VERSION ""

NS_ :

BS_:

BU_: Vector__XXX

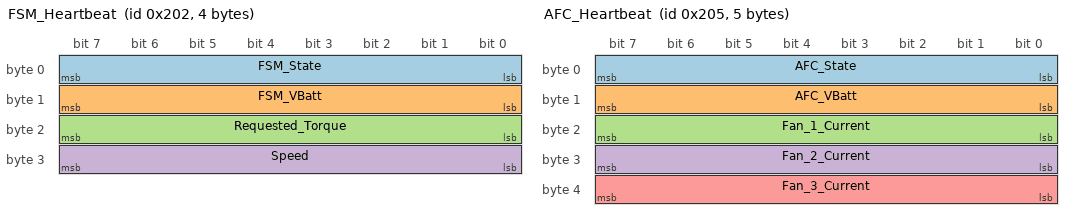
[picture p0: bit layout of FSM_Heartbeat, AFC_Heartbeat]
BO_ 514 FSM_Heartbeat: 4 Vector__XXX
SG_ FSM_State : 0|8@1+ (1,0) [0|255] "" Vector__XXX
SG_ FSM_VBatt : 8|8@1+ (0.066666,0) [0|16.99983] "V" Vector__XXX
SG_ Requested_Torque : 16|8@1+ (1,0) [0|255] "" Vector__XXX
SG_ Speed : 24|8@1+ (1,0) [0|255] "MPH" Vector__XXX

BO_ 516 DIM_Heartbeat: 3 Vector__XXX
SG_ DIM_State : 0|8@1+ (1,0) [0|255] "" Vector__XXX
SG_ Requested_State : 16|8@1+ (1,0) [0|255] "" Vector__XXX
SG_ DIM_VBatt : 8|8@1+ (0.066666,0) [0|16.99983] "V" Vector__XXX

BO_ 513 CC_Heartbeat: 2 Vector__XXX
SG_ CC_State : 0|8@1+ (1,0) [0|255] "" Vector__XXX
SG_ CC_VBatt : 8|8@1+ (0.066666,0) [0|16.99983] "V" Vector__XXX

BO_ 517 AFC_Heartbeat: 5 Vector__XXX
SG_ AFC_State : 0|8@1+ (1,0) [0|255] "" Vector__XXX
SG_ AFC_VBatt : 8|8@1+ (0.066666,0) [0|16.99983] "V" Vector__XXX
SG_ Fan_1_Current : 16|8@1+ (1,0) [0|255] "A" Vector__XXX
SG_ Fan_2_Current : 24|8@1+ (1,0) [0|255] "A" Vector__XXX
SG_ Fan_3_Current : 32|8@1+ (1,0) [0|255] "A" Vector__XXX

BO_ 518 TM_Heartbeat: 2 Vector__XXX
SG_ TM_State : 0|8@1+ (1,0) [0|255] "" Vector__XXX
SG_ TM_VBatt : 8|8@1+ (0.066666,0) [0|16.99983] "V" Vector__XXX

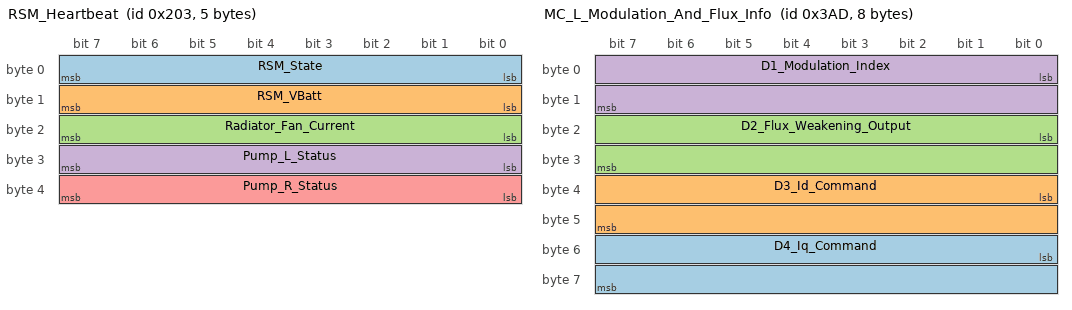
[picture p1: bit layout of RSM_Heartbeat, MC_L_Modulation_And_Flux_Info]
BO_ 515 RSM_Heartbeat: 5 Vector__XXX
SG_ RSM_State : 0|8@1+ (1,0) [0|255] "" Vector__XXX
SG_ RSM_VBatt : 8|8@1+ (0.066666,0) [0|16.99983] "" Vector__XXX
SG_ Radiator_Fan_Current : 16|8@1+ (1,0) [0|255] "mA" Vector__XXX
SG_ Pump_L_Status : 24|8@1+ (1,0) [0|255] "" Vector__XXX
SG_ Pump_R_Status : 32|8@1+ (1,0) [0|255] "" Vector__XXX

BO_ 512 SM_Heartbeat: 3 Vector__XXX
SG_ SM_State : 0|9@1+ (1,0) [0|511] "" Vector__XXX
SG_ SM_Vbatt : 8|8@1+ (0.066666,0) [0|16.99983] "V" Vector__XXX
SG_ Target_State : 16|8@1+ (1,0) [0|255] "" Vector__XXX

BO_ 941 MC_L_Modulation_And_Flux_Info: 8 Vector__XXX
SG_ D4_Iq_Command : 48|16@1- (0.1,0) [-3276.8|3276.7] "A" Vector__XXX
SG_ D3_Id_Command : 32|16@1- (0.1,0) [-3276.8|3276.7] "A" Vector__XXX
SG_ D2_Flux_Weakening_Output : 16|16@1- (0.1,0) [-3276.8|3276.7] "A" Vector__XXX
SG_ D1_Modulation_Index : 0|16@1- (0.0001,0) [-3.2768|3.2767] "" Vector__XXX

BO_ 940 MC_L_Torque_And_Timer_Info: 8 Vector__XXX
SG_ D3_Power_On_Timer : 32|32@1+ (0.003,0) [0|12884901.885] "Sec" Vector__XXX
SG_ D2_Torque_Feedback : 16|16@1- (0.1,0) [-3276.8|3276.7] "Nm" Vector__XXX
SG_ D1_Commanded_Torque : 0|16@1- (0.1,0) [-3276.8|3276.7] "Nm" Vector__XXX

BO_ 962 MC_L_Read_Write_Param_Response: 8 Vector__XXX
SG_ D2_Write_Success : 16|1@1+ (1,0) [0|1] "" Vector__XXX
SG_ D3_Data_Response : 32|16@1- (1,0) [-32768|32767] "" Vector__XXX
SG_ D1_Parameter_Address_Response : 0|16@1+ (1,0) [0|65535] "" Vector__XXX

BO_ 961 MC_L_Read_Write_Param_Command: 8 Vector__XXX
SG_ D3_Data_Command : 32|16@1- (1,0) [-32768|32767] "" Vector__XXX
SG_ D2_Read_Write_Command : 16|1@1+ (1,0) [0|1] "" Vector__XXX
SG_ D1_Parameter_Address_Command : 0|16@1+ (1,0) [0|65535] "" Vector__XXX

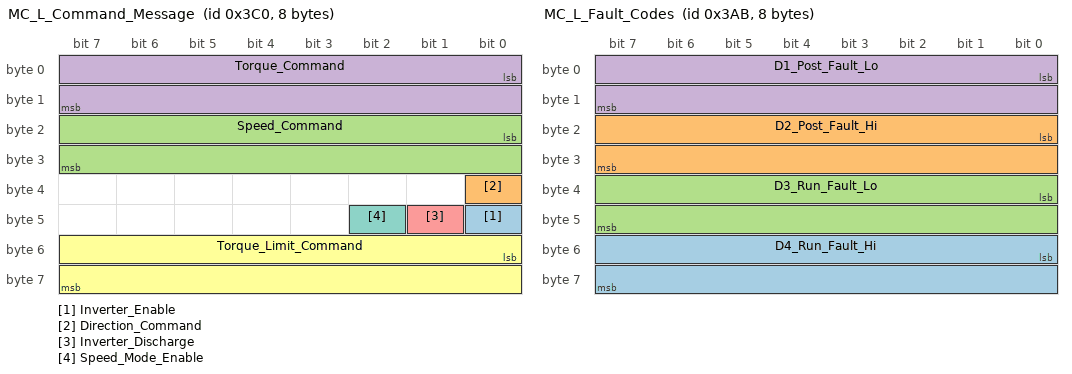
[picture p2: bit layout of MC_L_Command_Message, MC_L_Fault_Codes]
BO_ 960 MC_L_Command_Message: 8 Vector__XXX
SG_ Inverter_Enable : 40|1@1+ (1,0) [0|1] "Bit" Vector__XXX
SG_ Direction_Command : 32|1@1+ (1,0) [0|1] "Bit" Vector__XXX
SG_ Speed_Command : 16|16@1- (1,0) [-32768|32767] "rpm" Vector__XXX
SG_ Torque_Command : 0|16@1- (0.1,0) [-3276.8|3276.7] "Nm" Vector__XXX
SG_ Inverter_Discharge : 41|1@1+ (1,0) [0|1] "Bit" Vector__XXX
SG_ Torque_Limit_Command : 48|16@1- (1,0) [-3276.8|3276.7] "Nm" Vector__XXX
SG_ Speed_Mode_Enable : 42|1@1+ (1,0) [0|1] "Bit" Vector__XXX

BO_ 939 MC_L_Fault_Codes: 8 Vector__XXX
SG_ D4_Run_Fault_Hi : 48|16@1+ (1,0) [0|65535] "" Vector__XXX
SG_ D2_Post_Fault_Hi : 16|16@1+ (1,0) [0|65535] "" Vector__XXX
SG_ D3_Run_Fault_Lo : 32|16@1+ (1,0) [0|65535] "" Vector__XXX
SG_ D1_Post_Fault_Lo : 0|16@1+ (1,0) [0|65535] "" Vector__XXX

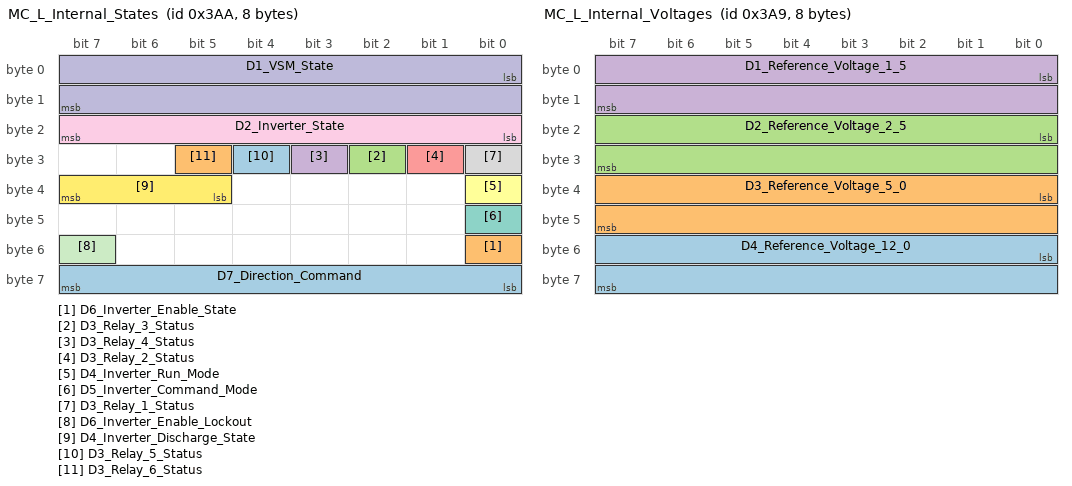
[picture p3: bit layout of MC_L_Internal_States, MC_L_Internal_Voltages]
BO_ 938 MC_L_Internal_States: 8 Vector__XXX
SG_ D7_Direction_Command : 56|8@1+ (1,0) [0|1] "" Vector__XXX
SG_ D6_Inverter_Enable_State : 48|1@1+ (1,0) [0|1] "" Vector__XXX
SG_ D3_Relay_3_Status : 26|1@1+ (1,0) [0|1] "" Vector__XXX
SG_ D3_Relay_4_Status : 27|1@1+ (1,0) [0|1] "" Vector__XXX
SG_ D3_Relay_2_Status : 25|1@1+ (1,0) [0|1] "" Vector__XXX
SG_ D4_Inverter_Run_Mode : 32|1@1+ (1,0) [0|1] "" Vector__XXX
SG_ D5_Inverter_Command_Mode : 40|1@1+ (1,0) [0|1] "" Vector__XXX
SG_ D3_Relay_1_Status : 24|1@1+ (1,0) [0|1] "" Vector__XXX
SG_ D2_Inverter_State : 16|8@1+ (1,0) [0|255] "" Vector__XXX
SG_ D1_VSM_State : 0|16@1+ (1,0) [0|15] "" Vector__XXX
SG_ D6_Inverter_Enable_Lockout : 55|1@1+ (1,0) [0|1] "" Vector__XXX
SG_ D4_Inverter_Discharge_State : 37|3@1+ (1,0) [0|7] "" Vector__XXX
SG_ D3_Relay_5_Status : 28|1@1+ (1,0) [0|1] "" Vector__XXX
SG_ D3_Relay_6_Status : 29|1@1+ (1,0) [0|1] "" Vector__XXX

BO_ 937 MC_L_Internal_Voltages: 8 Vector__XXX
SG_ D4_Reference_Voltage_12_0 : 48|16@1- (0.01,0) [-327.68|327.67] "V" Vector__XXX
SG_ D3_Reference_Voltage_5_0 : 32|16@1- (0.01,0) [-327.68|327.67] "V" Vector__XXX
SG_ D2_Reference_Voltage_2_5 : 16|16@1- (0.01,0) [-327.68|327.67] "V" Vector__XXX
SG_ D1_Reference_Voltage_1_5 : 0|16@1- (0.01,0) [-327.68|327.67] "V" Vector__XXX

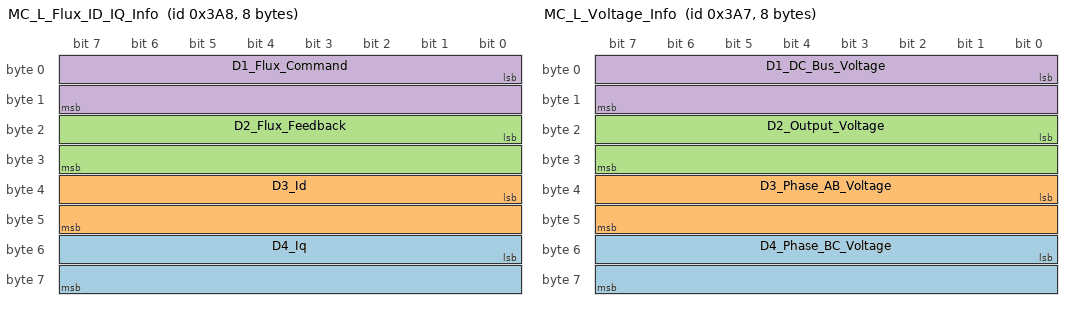
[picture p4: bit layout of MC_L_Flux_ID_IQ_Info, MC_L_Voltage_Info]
BO_ 936 MC_L_Flux_ID_IQ_Info: 8 Vector__XXX
SG_ D4_Iq : 48|16@1- (0.1,0) [-3276.8|3276.7] "A" Vector__XXX
SG_ D3_Id : 32|16@1- (0.1,0) [-3276.8|3276.7] "A" Vector__XXX
SG_ D2_Flux_Feedback : 16|16@1- (0.001,0) [-32.768|32.767] "Wb" Vector__XXX
SG_ D1_Flux_Command : 0|16@1- (0.001,0) [-32.768|32.767] "Wb" Vector__XXX

BO_ 935 MC_L_Voltage_Info: 8 Vector__XXX
SG_ D4_Phase_BC_Voltage : 48|16@1- (0.1,0) [-3276.8|3276.7] "V" Vector__XXX
SG_ D3_Phase_AB_Voltage : 32|16@1- (0.1,0) [-3276.8|3276.7] "V" Vector__XXX
SG_ D2_Output_Voltage : 16|16@1- (0.1,0) [-3276.8|3276.7] "V" Vector__XXX
SG_ D1_DC_Bus_Voltage : 0|16@1- (0.1,0) [-3276.8|3276.7] "V" Vector__XXX

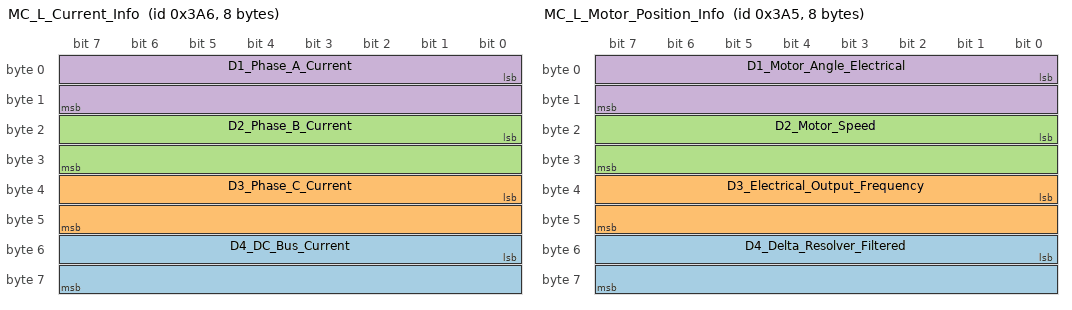
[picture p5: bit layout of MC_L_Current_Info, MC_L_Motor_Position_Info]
BO_ 934 MC_L_Current_Info: 8 Vector__XXX
SG_ D4_DC_Bus_Current : 48|16@1- (0.1,0) [-3276.8|3276.7] "A" Vector__XXX
SG_ D3_Phase_C_Current : 32|16@1- (0.1,0) [-3276.8|3276.7] "A" Vector__XXX
SG_ D2_Phase_B_Current : 16|16@1- (0.1,0) [-3276.8|3276.7] "A" Vector__XXX
SG_ D1_Phase_A_Current : 0|16@1- (0.1,0) [-3276.8|3276.7] "A" Vector__XXX

BO_ 933 MC_L_Motor_Position_Info: 8 Vector__XXX
SG_ D4_Delta_Resolver_Filtered : 48|16@1- (0.1,0) [-3276.8|3276.7] "deg" Vector__XXX
SG_ D3_Electrical_Output_Frequency : 32|16@1- (0.1,0) [-3276.8|3276.7] "hz" Vector__XXX
SG_ D2_Motor_Speed : 16|16@1- (1,0) [-32768|32767] "rpm" Vector__XXX
SG_ D1_Motor_Angle_Electrical : 0|16@1+ (0.1,0) [0|6553.5] "deg" Vector__XXX

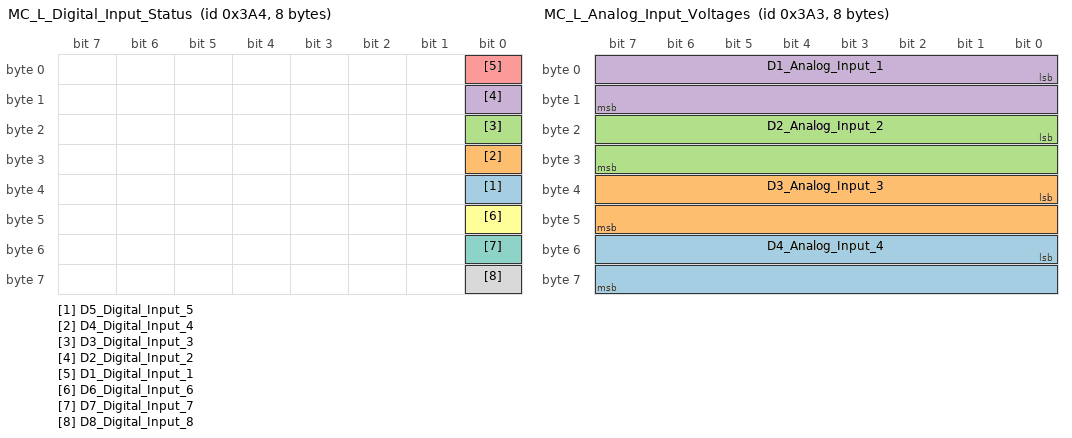
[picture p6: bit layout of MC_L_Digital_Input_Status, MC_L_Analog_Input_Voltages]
BO_ 932 MC_L_Digital_Input_Status: 8 Vector__XXX
SG_ D5_Digital_Input_5 : 32|1@1+ (1,0) [0|1] "boolean" Vector__XXX
SG_ D4_Digital_Input_4 : 24|1@1+ (1,0) [0|1] "boolean" Vector__XXX
SG_ D3_Digital_Input_3 : 16|1@1+ (1,0) [0|1] "boolean" Vector__XXX
SG_ D2_Digital_Input_2 : 8|1@1+ (1,0) [0|1] "boolean" Vector__XXX
SG_ D1_Digital_Input_1 : 0|1@1+ (1,0) [0|1] "boolean" Vector__XXX
SG_ D6_Digital_Input_6 : 40|1@1+ (1,0) [0|1] "boolean" Vector__XXX
SG_ D7_Digital_Input_7 : 48|1@1+ (1,0) [0|1] "boolean" Vector__XXX
SG_ D8_Digital_Input_8 : 56|1@1+ (1,0) [0|1] "boolean" Vector__XXX

BO_ 931 MC_L_Analog_Input_Voltages: 8 Vector__XXX
SG_ D4_Analog_Input_4 : 48|16@1- (0.01,0) [-327.68|327.67] "V" Vector__XXX
SG_ D3_Analog_Input_3 : 32|16@1- (0.01,0) [-327.68|327.67] "V" Vector__XXX
SG_ D2_Analog_Input_2 : 16|16@1- (0.01,0) [-327.68|327.67] "V" Vector__XXX
SG_ D1_Analog_Input_1 : 0|16@1- (0.01,0) [-327.68|327.67] "V" Vector__XXX

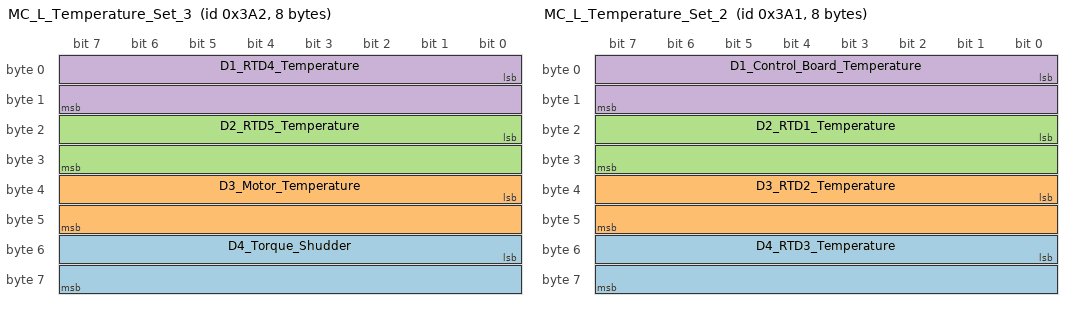
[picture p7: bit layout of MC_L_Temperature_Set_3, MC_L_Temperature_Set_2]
BO_ 930 MC_L_Temperature_Set_3: 8 Vector__XXX
SG_ D4_Torque_Shudder : 48|16@1- (0.1,0) [-3276.8|3276.7] "Nm" Vector__XXX
SG_ D3_Motor_Temperature : 32|16@1- (0.1,0) [-3276.8|3276.7] "degC" Vector__XXX
SG_ D2_RTD5_Temperature : 16|16@1- (0.1,0) [-3276.8|3276.7] "degC" Vector__XXX
SG_ D1_RTD4_Temperature : 0|16@1- (0.1,0) [-3276.8|3276.7] "degC" Vector__XXX

BO_ 929 MC_L_Temperature_Set_2: 8 Vector__XXX
SG_ D4_RTD3_Temperature : 48|16@1- (0.1,0) [-3276.8|3276.7] "degC" Vector__XXX
SG_ D3_RTD2_Temperature : 32|16@1- (0.1,0) [-3276.8|3276.7] "degC" Vector__XXX
SG_ D2_RTD1_Temperature : 16|16@1- (0.1,0) [-3276.8|3276.7] "degC" Vector__XXX
SG_ D1_Control_Board_Temperature : 0|16@1- (0.1,0) [-3276.8|3276.7] "degC" Vector__XXX

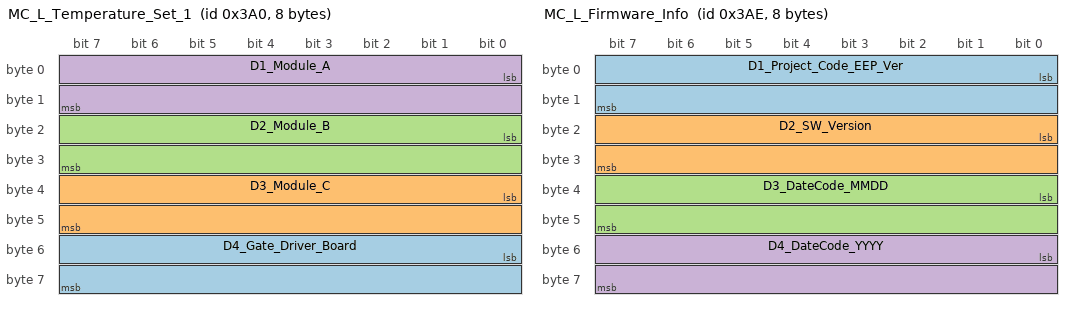
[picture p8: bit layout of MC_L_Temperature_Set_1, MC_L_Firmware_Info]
BO_ 928 MC_L_Temperature_Set_1: 8 Vector__XXX
SG_ D4_Gate_Driver_Board : 48|16@1- (0.1,0) [-3276.8|3276.7] "degC" Vector__XXX
SG_ D3_Module_C : 32|16@1- (0.1,0) [-3276.8|3276.7] "degC" Vector__XXX
SG_ D2_Module_B : 16|16@1- (0.1,0) [-3276.8|3276.7] "degC" Vector__XXX
SG_ D1_Module_A : 0|16@1- (0.1,0) [-3276.8|3276.7] "degC" Vector__XXX

BO_ 942 MC_L_Firmware_Info: 8 Vector__XXX
SG_ D1_Project_Code_EEP_Ver : 0|16@1+ (1,0) [0|65535] "" Vector__XXX
SG_ D2_SW_Version : 16|16@1+ (1,0) [0|65535] "" Vector__XXX
SG_ D3_DateCode_MMDD : 32|16@1+ (1,0) [0|65535] "" Vector__XXX
SG_ D4_DateCode_YYYY : 48|16@1+ (1,0) [0|65535] "" Vector__XXX

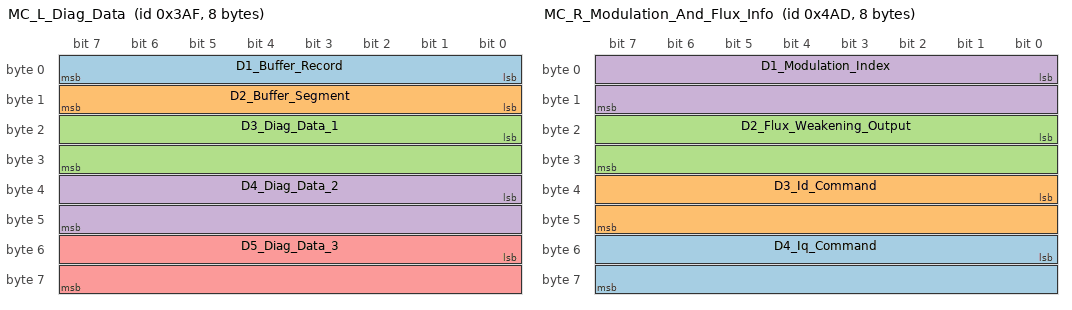
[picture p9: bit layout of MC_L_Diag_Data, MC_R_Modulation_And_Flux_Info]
BO_ 943 MC_L_Diag_Data: 8 Vector__XXX
SG_ D1_Buffer_Record : 0|8@1+ (1,0) [0|160] "" Vector__XXX
SG_ D2_Buffer_Segment : 8|8@1+ (1,0) [0|5] "" Vector__XXX
SG_ D3_Diag_Data_1 : 16|16@1- (1,0) [0|32767] "" Vector__XXX
SG_ D4_Diag_Data_2 : 32|16@1- (1,0) [0|32767] "" Vector__XXX
SG_ D5_Diag_Data_3 : 48|16@1- (1,0) [0|32767] "" Vector__XXX

BO_ 1197 MC_R_Modulation_And_Flux_Info: 8 Vector__XXX
SG_ D4_Iq_Command : 48|16@1- (0.1,0) [-3276.8|3276.7] "A" Vector__XXX
SG_ D3_Id_Command : 32|16@1- (0.1,0) [-3276.8|3276.7] "A" Vector__XXX
SG_ D2_Flux_Weakening_Output : 16|16@1- (0.1,0) [-3276.8|3276.7] "A" Vector__XXX
SG_ D1_Modulation_Index : 0|16@1- (0.0001,0) [-3.2768|3.2767] "" Vector__XXX

BO_ 1196 MC_R_Torque_And_Timer_Info: 8 Vector__XXX
SG_ D3_Power_On_Timer : 32|32@1+ (0.003,0) [0|12884901.885] "Sec" Vector__XXX
SG_ D2_Torque_Feedback : 16|16@1- (0.1,0) [-3276.8|3276.7] "Nm" Vector__XXX
SG_ D1_Commanded_Torque : 0|16@1- (0.1,0) [-3276.8|3276.7] "Nm" Vector__XXX

BO_ 1218 MC_R_Read_Write_Param_Response: 8 Vector__XXX
SG_ D2_Write_Success : 16|1@1+ (1,0) [0|1] "" Vector__XXX
SG_ D3_Data_Response : 32|16@1- (1,0) [-32768|32767] "" Vector__XXX
SG_ D1_Parameter_Address_Response : 0|16@1+ (1,0) [0|65535] "" Vector__XXX

BO_ 1217 MC_R_Read_Write_Param_Command: 8 Vector__XXX
SG_ D3_Data_Command : 32|16@1- (1,0) [-32768|32767] "" Vector__XXX
SG_ D2_Read_Write_Command : 16|1@1+ (1,0) [0|1] "" Vector__XXX
SG_ D1_Parameter_Address_Command : 0|16@1+ (1,0) [0|65535] "" Vector__XXX

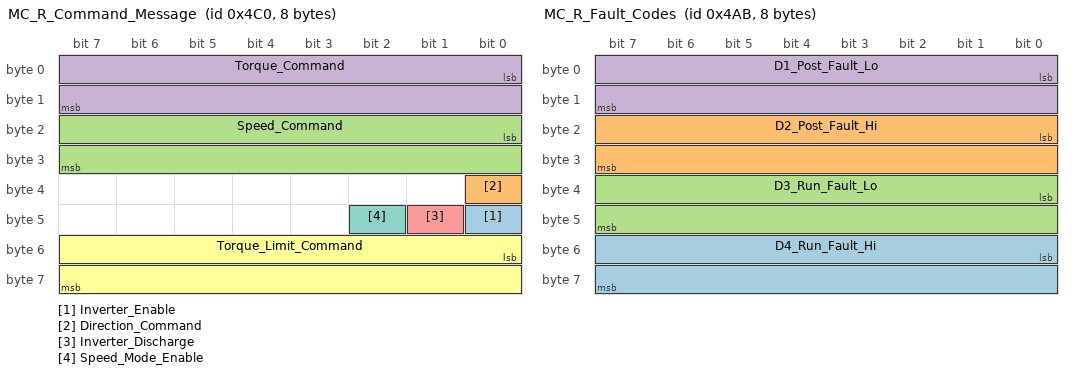
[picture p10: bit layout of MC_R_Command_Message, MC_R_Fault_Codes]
BO_ 1216 MC_R_Command_Message: 8 Vector__XXX
SG_ Inverter_Enable : 40|1@1+ (1,0) [0|1] "Bit" Vector__XXX
SG_ Direction_Command : 32|1@1+ (1,0) [0|1] "Bit" Vector__XXX
SG_ Speed_Command : 16|16@1- (1,0) [-32768|32767] "rpm" Vector__XXX
SG_ Torque_Command : 0|16@1- (0.1,0) [-3276.8|3276.7] "Nm" Vector__XXX
SG_ Inverter_Discharge : 41|1@1+ (1,0) [0|1] "Bit" Vector__XXX
SG_ Torque_Limit_Command : 48|16@1- (1,0) [-3276.8|3276.7] "Nm" Vector__XXX
SG_ Speed_Mode_Enable : 42|1@1+ (1,0) [0|1] "Bit" Vector__XXX

BO_ 1195 MC_R_Fault_Codes: 8 Vector__XXX
SG_ D4_Run_Fault_Hi : 48|16@1+ (1,0) [0|65535] "" Vector__XXX
SG_ D2_Post_Fault_Hi : 16|16@1+ (1,0) [0|65535] "" Vector__XXX
SG_ D3_Run_Fault_Lo : 32|16@1+ (1,0) [0|65535] "" Vector__XXX
SG_ D1_Post_Fault_Lo : 0|16@1+ (1,0) [0|65535] "" Vector__XXX

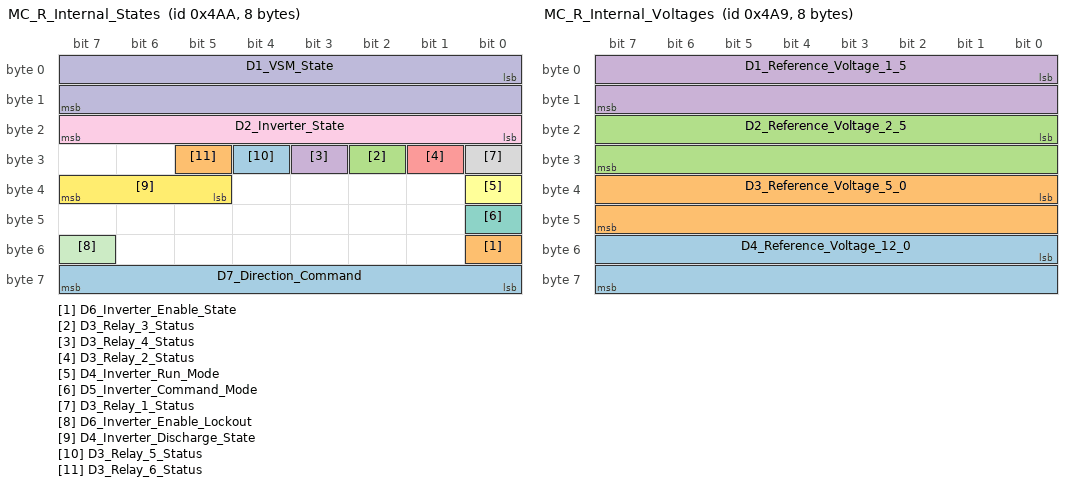
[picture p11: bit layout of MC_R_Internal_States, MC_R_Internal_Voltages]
BO_ 1194 MC_R_Internal_States: 8 Vector__XXX
SG_ D7_Direction_Command : 56|8@1+ (1,0) [0|1] "" Vector__XXX
SG_ D6_Inverter_Enable_State : 48|1@1+ (1,0) [0|1] "" Vector__XXX
SG_ D3_Relay_3_Status : 26|1@1+ (1,0) [0|1] "" Vector__XXX
SG_ D3_Relay_4_Status : 27|1@1+ (1,0) [0|1] "" Vector__XXX
SG_ D3_Relay_2_Status : 25|1@1+ (1,0) [0|1] "" Vector__XXX
SG_ D4_Inverter_Run_Mode : 32|1@1+ (1,0) [0|1] "" Vector__XXX
SG_ D5_Inverter_Command_Mode : 40|1@1+ (1,0) [0|1] "" Vector__XXX
SG_ D3_Relay_1_Status : 24|1@1+ (1,0) [0|1] "" Vector__XXX
SG_ D2_Inverter_State : 16|8@1+ (1,0) [0|255] "" Vector__XXX
SG_ D1_VSM_State : 0|16@1+ (1,0) [0|15] "" Vector__XXX
SG_ D6_Inverter_Enable_Lockout : 55|1@1+ (1,0) [0|1] "" Vector__XXX
SG_ D4_Inverter_Discharge_State : 37|3@1+ (1,0) [0|7] "" Vector__XXX
SG_ D3_Relay_5_Status : 28|1@1+ (1,0) [0|1] "" Vector__XXX
SG_ D3_Relay_6_Status : 29|1@1+ (1,0) [0|1] "" Vector__XXX

BO_ 1193 MC_R_Internal_Voltages: 8 Vector__XXX
SG_ D4_Reference_Voltage_12_0 : 48|16@1- (0.01,0) [-327.68|327.67] "V" Vector__XXX
SG_ D3_Reference_Voltage_5_0 : 32|16@1- (0.01,0) [-327.68|327.67] "V" Vector__XXX
SG_ D2_Reference_Voltage_2_5 : 16|16@1- (0.01,0) [-327.68|327.67] "V" Vector__XXX
SG_ D1_Reference_Voltage_1_5 : 0|16@1- (0.01,0) [-327.68|327.67] "V" Vector__XXX

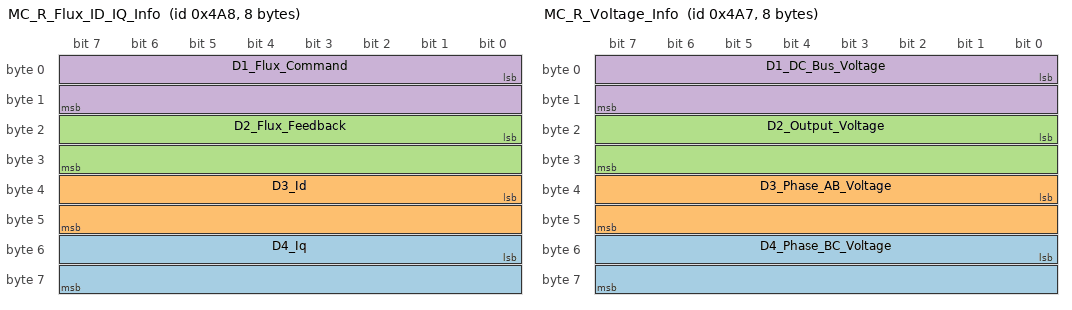
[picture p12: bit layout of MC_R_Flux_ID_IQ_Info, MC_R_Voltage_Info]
BO_ 1192 MC_R_Flux_ID_IQ_Info: 8 Vector__XXX
SG_ D4_Iq : 48|16@1- (0.1,0) [-3276.8|3276.7] "A" Vector__XXX
SG_ D3_Id : 32|16@1- (0.1,0) [-3276.8|3276.7] "A" Vector__XXX
SG_ D2_Flux_Feedback : 16|16@1- (0.001,0) [-32.768|32.767] "Wb" Vector__XXX
SG_ D1_Flux_Command : 0|16@1- (0.001,0) [-32.768|32.767] "Wb" Vector__XXX

BO_ 1191 MC_R_Voltage_Info: 8 Vector__XXX
SG_ D4_Phase_BC_Voltage : 48|16@1- (0.1,0) [-3276.8|3276.7] "V" Vector__XXX
SG_ D3_Phase_AB_Voltage : 32|16@1- (0.1,0) [-3276.8|3276.7] "V" Vector__XXX
SG_ D2_Output_Voltage : 16|16@1- (0.1,0) [-3276.8|3276.7] "V" Vector__XXX
SG_ D1_DC_Bus_Voltage : 0|16@1- (0.1,0) [-3276.8|3276.7] "V" Vector__XXX

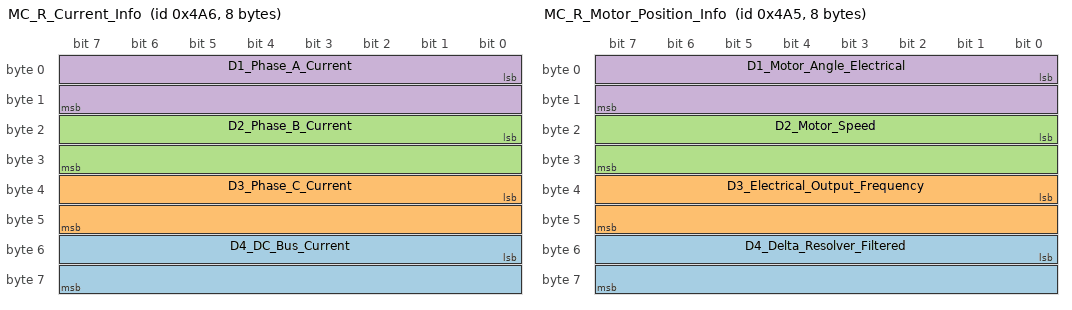
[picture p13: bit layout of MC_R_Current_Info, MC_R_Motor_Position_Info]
BO_ 1190 MC_R_Current_Info: 8 Vector__XXX
SG_ D4_DC_Bus_Current : 48|16@1- (0.1,0) [-3276.8|3276.7] "A" Vector__XXX
SG_ D3_Phase_C_Current : 32|16@1- (0.1,0) [-3276.8|3276.7] "A" Vector__XXX
SG_ D2_Phase_B_Current : 16|16@1- (0.1,0) [-3276.8|3276.7] "A" Vector__XXX
SG_ D1_Phase_A_Current : 0|16@1- (0.1,0) [-3276.8|3276.7] "A" Vector__XXX

BO_ 1189 MC_R_Motor_Position_Info: 8 Vector__XXX
SG_ D4_Delta_Resolver_Filtered : 48|16@1- (0.1,0) [-3276.8|3276.7] "deg" Vector__XXX
SG_ D3_Electrical_Output_Frequency : 32|16@1- (0.1,0) [-3276.8|3276.7] "hz" Vector__XXX
SG_ D2_Motor_Speed : 16|16@1- (1,0) [-32768|32767] "rpm" Vector__XXX
SG_ D1_Motor_Angle_Electrical : 0|16@1+ (0.1,0) [0|6553.5] "deg" Vector__XXX

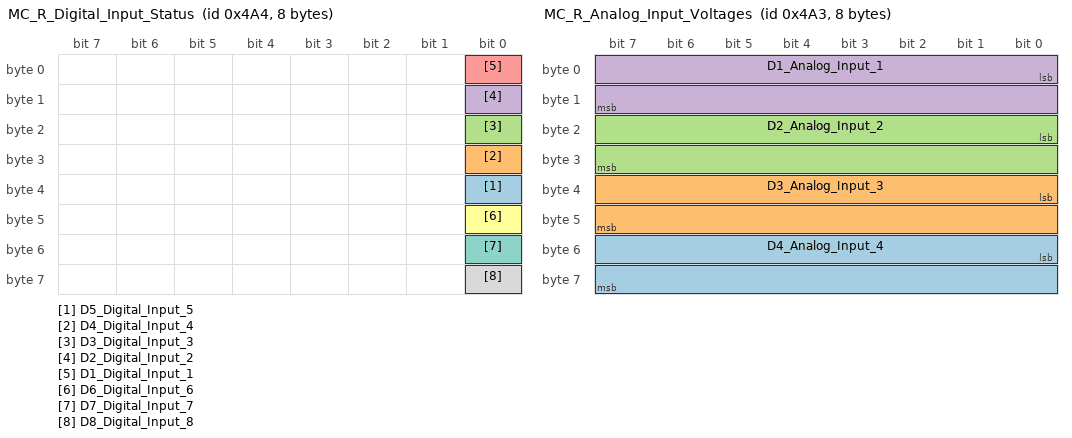
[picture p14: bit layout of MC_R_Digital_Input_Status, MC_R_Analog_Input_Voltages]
BO_ 1188 MC_R_Digital_Input_Status: 8 Vector__XXX
SG_ D5_Digital_Input_5 : 32|1@1+ (1,0) [0|1] "boolean" Vector__XXX
SG_ D4_Digital_Input_4 : 24|1@1+ (1,0) [0|1] "boolean" Vector__XXX
SG_ D3_Digital_Input_3 : 16|1@1+ (1,0) [0|1] "boolean" Vector__XXX
SG_ D2_Digital_Input_2 : 8|1@1+ (1,0) [0|1] "boolean" Vector__XXX
SG_ D1_Digital_Input_1 : 0|1@1+ (1,0) [0|1] "boolean" Vector__XXX
SG_ D6_Digital_Input_6 : 40|1@1+ (1,0) [0|1] "boolean" Vector__XXX
SG_ D7_Digital_Input_7 : 48|1@1+ (1,0) [0|1] "boolean" Vector__XXX
SG_ D8_Digital_Input_8 : 56|1@1+ (1,0) [0|1] "boolean" Vector__XXX

BO_ 1187 MC_R_Analog_Input_Voltages: 8 Vector__XXX
SG_ D4_Analog_Input_4 : 48|16@1- (0.01,0) [-327.68|327.67] "V" Vector__XXX
SG_ D3_Analog_Input_3 : 32|16@1- (0.01,0) [-327.68|327.67] "V" Vector__XXX
SG_ D2_Analog_Input_2 : 16|16@1- (0.01,0) [-327.68|327.67] "V" Vector__XXX
SG_ D1_Analog_Input_1 : 0|16@1- (0.01,0) [-327.68|327.67] "V" Vector__XXX

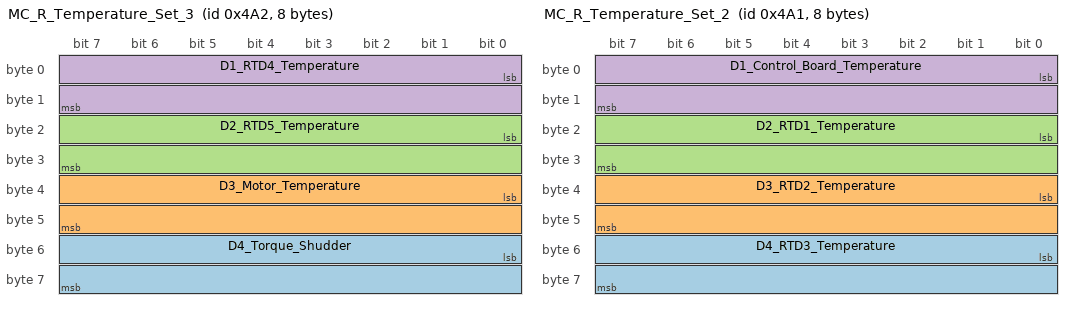
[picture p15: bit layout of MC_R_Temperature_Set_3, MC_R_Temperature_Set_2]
BO_ 1186 MC_R_Temperature_Set_3: 8 Vector__XXX
SG_ D4_Torque_Shudder : 48|16@1- (0.1,0) [-3276.8|3276.7] "Nm" Vector__XXX
SG_ D3_Motor_Temperature : 32|16@1- (0.1,0) [-3276.8|3276.7] "degC" Vector__XXX
SG_ D2_RTD5_Temperature : 16|16@1- (0.1,0) [-3276.8|3276.7] "degC" Vector__XXX
SG_ D1_RTD4_Temperature : 0|16@1- (0.1,0) [-3276.8|3276.7] "degC" Vector__XXX

BO_ 1185 MC_R_Temperature_Set_2: 8 Vector__XXX
SG_ D4_RTD3_Temperature : 48|16@1- (0.1,0) [-3276.8|3276.7] "degC" Vector__XXX
SG_ D3_RTD2_Temperature : 32|16@1- (0.1,0) [-3276.8|3276.7] "degC" Vector__XXX
SG_ D2_RTD1_Temperature : 16|16@1- (0.1,0) [-3276.8|3276.7] "degC" Vector__XXX
SG_ D1_Control_Board_Temperature : 0|16@1- (0.1,0) [-3276.8|3276.7] "degC" Vector__XXX

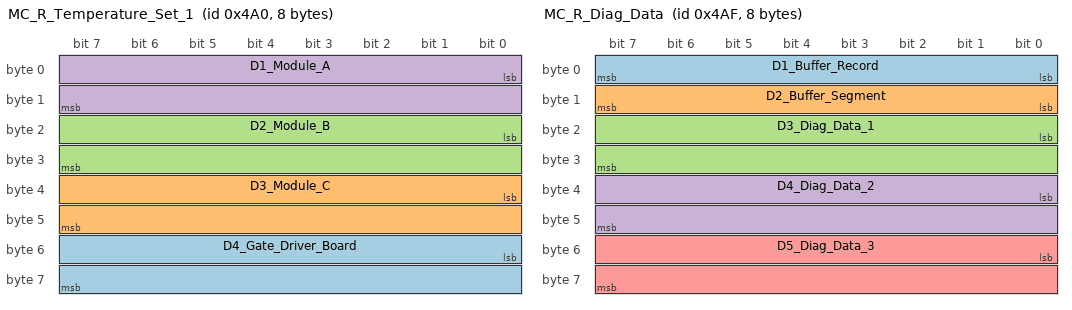
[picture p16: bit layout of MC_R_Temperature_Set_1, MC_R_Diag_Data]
BO_ 1184 MC_R_Temperature_Set_1: 8 Vector__XXX
SG_ D4_Gate_Driver_Board : 48|16@1- (0.1,0) [-3276.8|3276.7] "degC" Vector__XXX
SG_ D3_Module_C : 32|16@1- (0.1,0) [-3276.8|3276.7] "degC" Vector__XXX
SG_ D2_Module_B : 16|16@1- (0.1,0) [-3276.8|3276.7] "degC" Vector__XXX
SG_ D1_Module_A : 0|16@1- (0.1,0) [-3276.8|3276.7] "degC" Vector__XXX

BO_ 1198 MC_R_Firmware_Info: 8 Vector__XXX
SG_ D1_Project_Code_EEP_Ver : 0|16@1+ (1,0) [0|65535] "" Vector__XXX
SG_ D2_SW_Version : 16|16@1+ (1,0) [0|65535] "" Vector__XXX
SG_ D3_DateCode_MMDD : 32|16@1+ (1,0) [0|65535] "" Vector__XXX
SG_ D4_DateCode_YYYY : 48|16@1+ (1,0) [0|65535] "" Vector__XXX

BO_ 1199 MC_R_Diag_Data: 8 Vector__XXX
SG_ D1_Buffer_Record : 0|8@1+ (1,0) [0|160] "" Vector__XXX
SG_ D2_Buffer_Segment : 8|8@1+ (1,0) [0|5] "" Vector__XXX
SG_ D3_Diag_Data_1 : 16|16@1- (1,0) [0|32767] "" Vector__XXX
SG_ D4_Diag_Data_2 : 32|16@1- (1,0) [0|32767] "" Vector__XXX
SG_ D5_Diag_Data_3 : 48|16@1- (1,0) [0|32767] "" Vector__XXX

BO_ 1280 BMS_BMU_Heartbeat_SN: 8 Vector__XXX
SG_ Device_ID : 0|32@1+ (1,0) [0|4294967295] "" Vector__XXX
SG_ Device_Serial : 32|32@1+ (1,0) [0|4294967295] "" Vector__XXX

BO_ 1520 BMS_Factory_Config_Calibration: 8 Vector__XXX

BO_ 1524 BMS_Pack_SOC: 8 Vector__XXX
SG_ BMS_Pack_SOC_Ah : 0|32@1- (1,0) [-3.4E038|3.4E038] "Ah" Vector__XXX
SG_ BMS_Pack_SOC_Percent : 32|32@1- (1,0) [-3.4E038|3.4E038] "%" Vector__XXX

BO_ 1525 BMS_Balance_SOC: 8 Vector__XXX
SG_ BMS_Balance_SOC_Ah : 0|32@1- (1,0) [-3.4E038|3.4E038] "Ah" Vector__XXX
SG_ BMS_Balance_SOC_Percent : 32|32@1- (1,0) [-3.4E038|3.4E038] "%" Vector__XXX

BO_ 1526 BMS_Charger_Control_Info: 8 Vector__XXX
SG_ BMS_Charging_Cell_Voltage_Error : 0|16@1+ (1,0) [0|65535] "mV" Vector__XXX
SG_ BMS_Cell_Temp_Margin : 16|16@1+ (1,0) [0|65535] "1/10 C" Vector__XXX
SG_ BMS_Discharge_Cell_Voltage_Error : 32|16@1+ (1,0) [0|65535] "mV" Vector__XXX
SG_ BMS_Total_Pack_Capacity : 48|16@1+ (1,0) [0|65535] "Ah" Vector__XXX

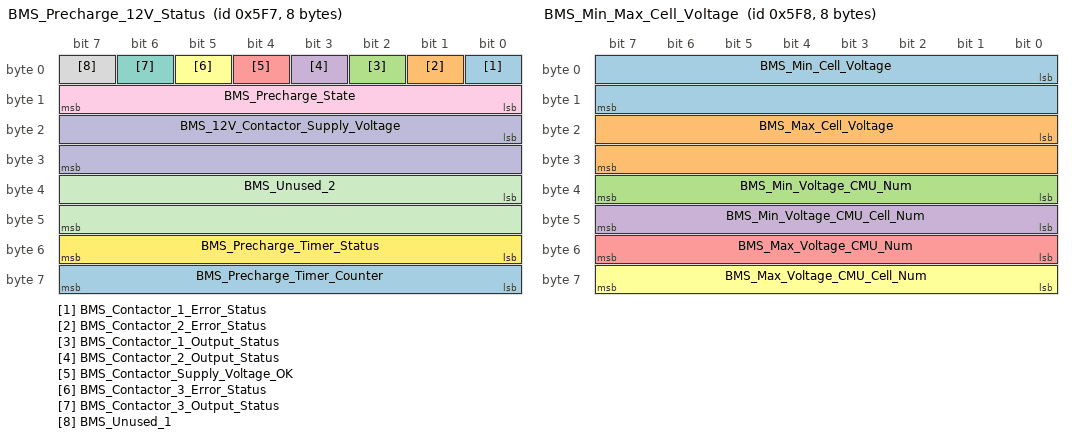
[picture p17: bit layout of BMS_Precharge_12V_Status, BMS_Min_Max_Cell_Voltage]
BO_ 1527 BMS_Precharge_12V_Status: 8 Vector__XXX
SG_ BMS_Contactor_1_Error_Status : 0|1@1+ (1,0) [0|1] "" Vector__XXX
SG_ BMS_Contactor_2_Error_Status : 1|1@1+ (1,0) [0|1] "" Vector__XXX
SG_ BMS_Contactor_1_Output_Status : 2|1@1+ (1,0) [0|1] "" Vector__XXX
SG_ BMS_Contactor_2_Output_Status : 3|1@1+ (1,0) [0|1] "" Vector__XXX
SG_ BMS_Contactor_Supply_Voltage_OK : 4|1@1+ (1,0) [0|1] "" Vector__XXX
SG_ BMS_Contactor_3_Error_Status : 5|1@1+ (1,0) [0|1] "" Vector__XXX
SG_ BMS_Contactor_3_Output_Status : 6|1@1+ (1,0) [0|1] "" Vector__XXX
SG_ BMS_Unused_1 : 7|1@1+ (1,0) [0|1] "" Vector__XXX
SG_ BMS_Precharge_State : 8|8@1+ (1,0) [0|255] "" Vector__XXX
SG_ BMS_12V_Contactor_Supply_Voltage : 16|16@1+ (1,0) [0|65535] "mV" Vector__XXX
SG_ BMS_Unused_2 : 32|16@1+ (1,0) [0|65535] "" Vector__XXX
SG_ BMS_Precharge_Timer_Status : 48|8@1+ (1,0) [0|255] "" Vector__XXX
SG_ BMS_Precharge_Timer_Counter : 56|8@1+ (1,0) [0|255] "" Vector__XXX

BO_ 1528 BMS_Min_Max_Cell_Voltage: 8 Vector__XXX
SG_ BMS_Min_Cell_Voltage : 0|16@1+ (1,0) [0|65535] "mV" Vector__XXX
SG_ BMS_Max_Cell_Voltage : 16|16@1+ (1,0) [0|65535] "mV" Vector__XXX
SG_ BMS_Min_Voltage_CMU_Num : 32|8@1+ (1,0) [0|255] "" Vector__XXX
SG_ BMS_Min_Voltage_CMU_Cell_Num : 40|8@1+ (1,0) [0|255] "" Vector__XXX
SG_ BMS_Max_Voltage_CMU_Num : 48|8@1+ (1,0) [0|255] "" Vector__XXX
SG_ BMS_Max_Voltage_CMU_Cell_Num : 56|8@1+ (1,0) [0|255] "" Vector__XXX

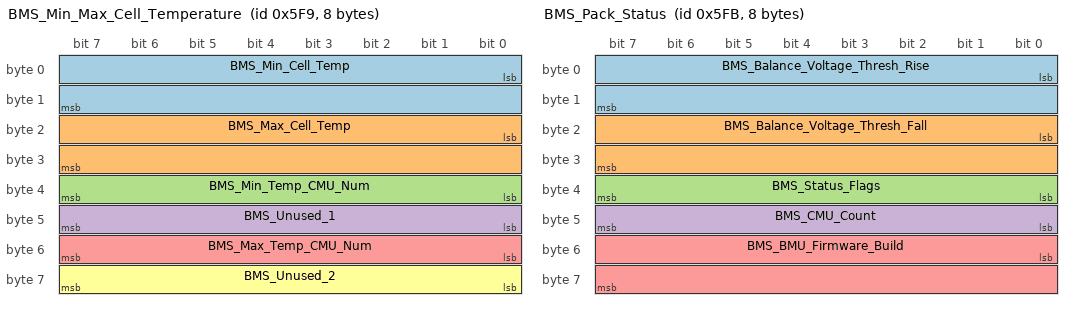
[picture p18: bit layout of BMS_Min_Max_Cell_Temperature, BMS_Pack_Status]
BO_ 1529 BMS_Min_Max_Cell_Temperature: 8 Vector__XXX
SG_ BMS_Min_Cell_Temp : 0|16@1+ (1,0) [0|65535] "1/10 C" Vector__XXX
SG_ BMS_Max_Cell_Temp : 16|16@1+ (1,0) [0|65535] "1/10 C" Vector__XXX
SG_ BMS_Min_Temp_CMU_Num : 32|8@1+ (1,0) [0|255] "" Vector__XXX
SG_ BMS_Unused_1 : 40|8@1+ (1,0) [0|255] "" Vector__XXX
SG_ BMS_Max_Temp_CMU_Num : 48|8@1+ (1,0) [0|255] "" Vector__XXX
SG_ BMS_Unused_2 : 56|8@1+ (1,0) [0|255] "" Vector__XXX

BO_ 1530 BMS_Pack_Voltage_Current: 8 Vector__XXX
SG_ BMU_Battery_Voltage : 0|32@1+ (1,0) [0|4294967295] "V" Vector__XXX
SG_ BMU_Battery_Current : 32|32@1+ (1,0) [0|4294967295] "mA" Vector__XXX

BO_ 1531 BMS_Pack_Status: 8 Vector__XXX
SG_ BMS_Balance_Voltage_Thresh_Rise : 0|16@1+ (1,0) [0|65535] "" Vector__XXX
SG_ BMS_Balance_Voltage_Thresh_Fall : 16|16@1+ (1,0) [0|65535] "" Vector__XXX
SG_ BMS_Status_Flags : 32|8@1+ (1,0) [0|255] "" Vector__XXX
SG_ BMS_CMU_Count : 40|8@1+ (1,0) [0|255] "" Vector__XXX
SG_ BMS_BMU_Firmware_Build : 48|16@1+ (1,0) [0|65535] "" Vector__XXX

BO_ 1532 BMS_Fan_12V_Status: 8 Vector__XXX
SG_ BMS_Fan_Speed_0 : 0|16@1+ (1,0) [0|65535] "RPM" Vector__XXX
SG_ BMS_Fan_Speed_1 : 16|16@1+ (1,0) [0|65535] "RPM" Vector__XXX
SG_ BMS_12V_Fan_Contactor_Current : 32|16@1+ (1,0) [0|65535] "mA" Vector__XXX
SG_ BMS_12V_CMU_Current : 48|16@1+ (1,0) [0|65535] "mA" Vector__XXX

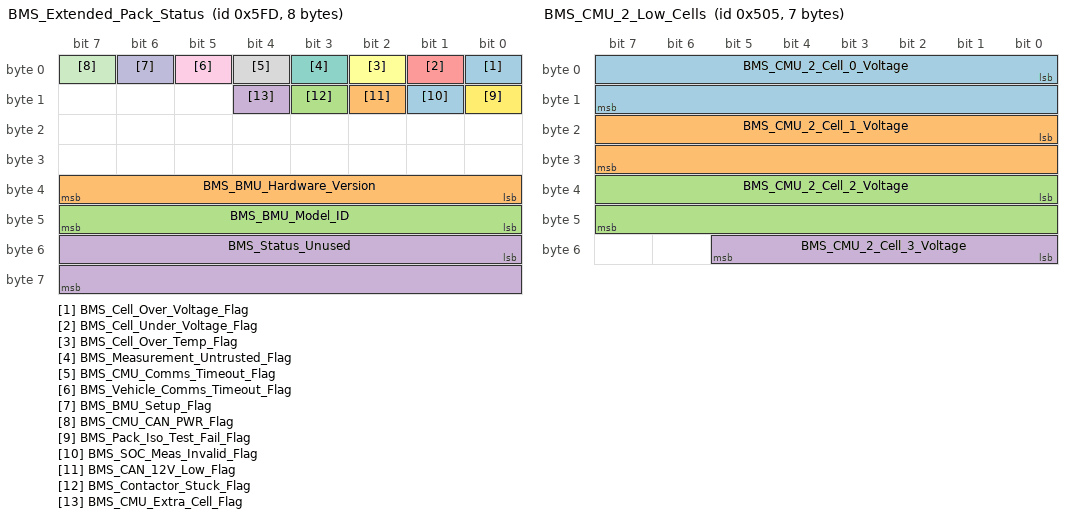
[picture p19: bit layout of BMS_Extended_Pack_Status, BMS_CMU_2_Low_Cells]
BO_ 1533 BMS_Extended_Pack_Status: 8 Vector__XXX
SG_ BMS_Cell_Over_Voltage_Flag : 0|1@1+ (1,0) [0|1] "" Vector__XXX
SG_ BMS_BMU_Hardware_Version : 32|8@1+ (1,0) [0|255] "" Vector__XXX
SG_ BMS_BMU_Model_ID : 40|8@1+ (1,0) [0|255] "" Vector__XXX
SG_ BMS_Status_Unused : 48|16@1+ (1,0) [0|65535] "" Vector__XXX
SG_ BMS_Cell_Under_Voltage_Flag : 1|1@1+ (1,0) [0|1] "" Vector__XXX
SG_ BMS_Cell_Over_Temp_Flag : 2|1@1+ (1,0) [0|1] "" Vector__XXX
SG_ BMS_Measurement_Untrusted_Flag : 3|1@1+ (1,0) [0|1] "" Vector__XXX
SG_ BMS_CMU_Comms_Timeout_Flag : 4|1@1+ (1,0) [0|1] "" Vector__XXX
SG_ BMS_Vehicle_Comms_Timeout_Flag : 5|1@1+ (1,0) [0|1] "" Vector__XXX
SG_ BMS_BMU_Setup_Flag : 6|1@1+ (1,0) [0|1] "" Vector__XXX
SG_ BMS_CMU_CAN_PWR_Flag : 7|1@1+ (1,0) [0|1] "" Vector__XXX
SG_ BMS_Pack_Iso_Test_Fail_Flag : 8|1@1+ (1,0) [0|1] "" Vector__XXX
SG_ BMS_SOC_Meas_Invalid_Flag : 9|1@1+ (1,0) [0|1] "" Vector__XXX
SG_ BMS_CAN_12V_Low_Flag : 10|1@1+ (1,0) [0|1] "" Vector__XXX
SG_ BMS_Contactor_Stuck_Flag : 11|1@1+ (1,0) [0|1] "" Vector__XXX
SG_ BMS_CMU_Extra_Cell_Flag : 12|1@1+ (1,0) [0|1] "" Vector__XXX

BO_ 2032 BMS_Bootloader_1: 8 Vector__XXX

BO_ 2033 BMS_Bootloader_2: 8 Vector__XXX

BO_ 2034 BMS_Bootloader_3: 8 Vector__XXX

BO_ 2035 BMS_Bootloader_4: 8 Vector__XXX

BO_ 2036 BMS_Bootloader_5: 8 Vector__XXX

BO_ 1281 BMS_CMU_1_Status: 8 Vector__XXX
SG_ BMS_CMU_1_SN : 0|32@1+ (1,0) [0|4294967295] "" Vector__XXX
SG_ BMS_CMU_1_PCB_Temp : 32|16@1+ (1,0) [0|65535] "" Vector__XXX
SG_ BMS_CMU_1_Cell_Temp : 48|16@1+ (1,0) [0|65535] "" Vector__XXX

BO_ 1282 BMS_CMU_1_Low_Cells: 8 Vector__XXX
SG_ BMS_CMU_1_Cell_0_Voltage : 0|16@1+ (1,0) [0|65535] "mV" Vector__XXX
SG_ BMS_CMU_1_Cell_1_Voltage : 16|16@1+ (1,0) [0|65535] "mV" Vector__XXX
SG_ BMS_CMU_1_Cell_2_Voltage : 32|16@1+ (1,0) [0|65535] "mV" Vector__XXX
SG_ BMS_CMU_1_Cell_3_Voltage : 48|16@1+ (1,0) [0|65535] "mV" Vector__XXX

BO_ 1283 BMS_CMU_1_High_Cells: 8 Vector__XXX
SG_ BMS_CMU_1_Cell_4_Voltage : 0|16@1+ (1,0) [0|65535] "" Vector__XXX
SG_ BMS_CMU_1_Cell_5_Voltage : 16|16@1+ (1,0) [0|65535] "mV" Vector__XXX
SG_ BMS_CMU_1_Cell_6_Voltage : 32|16@1+ (1,0) [0|65535] "mV" Vector__XXX
SG_ BMS_CMU_1_Cell_7_Voltage : 48|16@1+ (1,0) [0|65535] "mV" Vector__XXX

BO_ 1284 BMS_CMU_2_Status: 8 Vector__XXX
SG_ BMS_CMU_2_SN : 0|32@1+ (1,0) [0|4294967295] "" Vector__XXX
SG_ BMS_CMU_2_PCB_Temp : 32|16@1+ (1,0) [0|65535] "" Vector__XXX
SG_ BMS_CMU_2_Cell_Temp : 48|16@1+ (1,0) [0|65535] "" Vector__XXX

BO_ 1285 BMS_CMU_2_Low_Cells: 7 Vector__XXX
SG_ BMS_CMU_2_Cell_0_Voltage : 0|16@1+ (1,0) [0|65535] "mV" Vector__XXX
SG_ BMS_CMU_2_Cell_1_Voltage : 16|16@1+ (1,0) [0|65535] "mV" Vector__XXX
SG_ BMS_CMU_2_Cell_2_Voltage : 32|16@1+ (1,0) [0|65535] "mV" Vector__XXX
SG_ BMS_CMU_2_Cell_3_Voltage : 48|6@1+ (1,0) [0|63] "mV" Vector__XXX

BO_ 1286 BMS_CMU_2_High_Cells: 8 Vector__XXX
SG_ BMS_CMU_2_Cell_4_Voltage : 0|16@1+ (1,0) [0|65535] "" Vector__XXX
SG_ BMS_CMU_2_Cell_5_Voltage : 16|16@1+ (1,0) [0|65535] "" Vector__XXX
SG_ BMS_CMU_2_Cell_6_Voltage : 32|16@1+ (1,0) [0|65535] "" Vector__XXX
SG_ BMS_CMU_2_Cell_7_Voltage : 48|16@1+ (1,0) [0|65535] "" Vector__XXX

BO_ 1287 BMS_CMU_3_Status: 1 Vector__XXX

BO_ 1290 BMS_CMU_4_Status: 1 Vector__XXX

BO_ 1293 BMS_CMU_5_Status: 1 Vector__XXX

BO_ 1296 BMS_CMU_6_Status: 1 Vector__XXX

BO_ 1299 BMS_CMU_7_Status: 1 Vector__XXX

BO_ 1302 BMS_CMU_8_Status: 1 Vector__XXX

BO_ 1305 BMS_CMU_9_Status: 1 Vector__XXX

BO_ 1308 BMS_CMU_10_Status: 1 Vector__XXX

BO_ 1311 BMS_CMU_11_Status: 1 Vector__XXX

BO_ 1314 BMS_CMU_12_Status: 1 Vector__XXX

BO_ 1288 BMS_CMU_3_Low_Cells: 1 Vector__XXX

BO_ 1291 BMS_CMU_4_Low_Cells: 1 Vector__XXX

BO_ 1294 BMS_CMU_5_Low_Cells: 1 Vector__XXX

BO_ 1297 BMS_CMU_6_Low_Cells: 1 Vector__XXX

BO_ 1300 BMS_CMU_7_Low_Cells: 1 Vector__XXX

BO_ 1303 BMS_CMU_8_Low_Cells: 1 Vector__XXX

BO_ 1306 BMS_CMU_9_Low_Cells: 1 Vector__XXX

BO_ 1309 BMS_CMU_10_Low_Cells: 1 Vector__XXX

BO_ 1312 BMS_CMU_11_Low_Cells: 1 Vector__XXX

BO_ 1315 BMS_CMU_12_Low_Cells: 1 Vector__XXX

BO_ 1289 BMS_CMU_3_High_Cells: 1 Vector__XXX

BO_ 1292 BMS_CMU_4_High_Cells: 1 Vector__XXX

BO_ 1295 BMS_CMU_5_High_Cells: 1 Vector__XXX

BO_ 1298 BMS_CMU_6_High_Cells: 1 Vector__XXX

BO_ 1301 BMS_CMU_7_High_Cells: 1 Vector__XXX

BO_ 1304 BMS_CMU_8_High_Cells: 1 Vector__XXX

BO_ 1307 BMS_CMU_9_High_Cells: 1 Vector__XXX

BO_ 1310 BMS_CMU_10_High_Cells: 1 Vector__XXX

BO_ 1313 BMS_CMU_11_High_Cells: 1 Vector__XXX

BO_ 1316 BMS_CMU_12_High_Cells: 1 Vector__XXX

CM_ BO_ 514 "Front Sensor Module Heartbeat";
CM_ SG_ 514 FSM_State "Current Module State";
CM_ BO_ 516 "Driver Interface Module Hearbeat";
CM_ SG_ 941 D4_Iq_Command "The commanded Q-axis current";
CM_ SG_ 941 D3_Id_Command "The commanded D-axis current";
CM_ SG_ 941 D2_Flux_Weakening_Output "This is the current output of the flux regulator.";
CM_ SG_ 941 D1_Modulation_Index "This is the modulation index. The scale factor is x100. To get the actual modulation index divide the value by 100.";
CM_ SG_ 940 D3_Power_On_Timer "Updated every 3 msec. This will roll over in approximately 150 days!";
CM_ SG_ 940 D2_Torque_Feedback "Estimated motor torque feedback";
CM_ SG_ 940 D1_Commanded_Torque "The commanded Torque";
CM_ BO_ 962 "To write a parameter use message 0x0C1 with byte #2 set to 1 (write). To read a parameter use message 0x0C1 with byte #2 to set 0 (read). ";
CM_ SG_ 962 D2_Write_Success "0=Write failure, 1=Success";
CM_ SG_ 962 D3_Data_Response "All EEPROM data is 16 bits and is contained in bytes 4 and 5. Bytes 6 and 7 should be ignored.";
CM_ SG_ 962 D1_Parameter_Address_Response "Valid EEPROM Parameter CAN addresses are between 100 and 499.";
CM_ BO_ 961 "To write a parameter use message 0x0C1 with byte #2 set to 1 (write). To read a parameter use message 0x0C1 with byte #2 to set 0 (read). ";
CM_ SG_ 961 D3_Data_Command "All EEPROM data is 16 bits and is contained in bytes 4 and 5.";
CM_ SG_ 961 D2_Read_Write_Command "0=Read, 1=Write";
CM_ SG_ 961 D1_Parameter_Address_Command "Valid EEPROM Parameter CAN addresses are between 100 and 499.";
CM_ BO_ 960 "The command message is used to transmit data to the controller. This message is sent from a user supplied external controller to the PMxxx controller.";
CM_ SG_ 960 Inverter_Enable "0=Inverter OFF, 1 = Inverter ON";
CM_ SG_ 960 Direction_Command "0=CW, 1=CCW as veiwed from the shaft end of the motor";
CM_ SG_ 960 Speed_Command "Speed commandused when in speed mode";
CM_ SG_ 960 Torque_Command "Torque command when in torque mode";
CM_ SG_ 960 Inverter_Discharge "0=Discharge Disable,=Discharge Enable";
CM_ SG_ 960 Torque_Limit_Command "Torque Limit, set to 0 to keep default";
CM_ SG_ 960 Speed_Mode_Enable "0 = No change to mode, 1 = change to speed mode from torque mode";
CM_ SG_ 939 D4_Run_Fault_Hi "Each bit represents a fault. Please refer to PM100 Users Manual for details.";
CM_ SG_ 939 D2_Post_Fault_Hi "Each bit represents a fault. Please refer to PM100 Users Manual for details.";
CM_ SG_ 939 D3_Run_Fault_Lo "Each bit represents a fault. Please refer to PM100 Users Manual for details.";
CM_ SG_ 939 D1_Post_Fault_Lo "Each bit represents a fault. Please refer to PM100 Users Manual for details.";
CM_ SG_ 938 D7_Direction_Command "1 = Forward0 = 'Reverse' if inverter enabled  & 'Stopped' if inverter is disabled";
CM_ SG_ 938 D6_Inverter_Enable_State "0=Inverter Disabled, 1=Inverter Enabled";
CM_ SG_ 938 D3_Relay_3_Status "0=OFF, 1=ON";
CM_ SG_ 938 D3_Relay_4_Status "0=OFF, 1=ON";
CM_ SG_ 938 D3_Relay_2_Status "0=OFF, 1=ON";
CM_ SG_ 938 D4_Inverter_Run_Mode "0=Torque Mode, 1=Speed Mode";
CM_ SG_ 938 D5_Inverter_Command_Mode "0=CAN mode, 1=VSM mode";
CM_ SG_ 938 D3_Relay_1_Status "0=OFF, 1=ON";
CM_ SG_ 938 D2_Inverter_State "Different states for the inverter state machine";
CM_ SG_ 938 D1_VSM_State "Different states for the vehicle state machine";
CM_ SG_ 938 D6_Inverter_Enable_Lockout "0=Lockout Disabled, 1=Lockout Enabled";
CM_ SG_ 938 D4_Inverter_Discharge_State "0 = Disabled, 1 = Enabled, 2 = Speed Check, 3 = Active, 4 = Complete";
CM_ SG_ 938 D3_Relay_5_Status "0=OFF, 1=ON";
CM_ SG_ 938 D3_Relay_6_Status "0=OFF, 1=ON";
CM_ SG_ 937 D4_Reference_Voltage_12_0 "12V Input Voltage";
CM_ SG_ 937 D3_Reference_Voltage_5_0 "Transducer voltage";
CM_ SG_ 937 D2_Reference_Voltage_2_5 "Internal reference voltage";
CM_ SG_ 937 D1_Reference_Voltage_1_5 "Internal reference voltage";
CM_ SG_ 936 D4_Iq "The measured Iq current";
CM_ SG_ 936 D3_Id "The measured Id current";
CM_ SG_ 936 D2_Flux_Feedback "The estimated flux";
CM_ SG_ 936 D1_Flux_Command "The commanded flux";
CM_ SG_ 935 D4_Phase_BC_Voltage "Measured value of the voltage between Phase B and Phase C";
CM_ SG_ 935 D3_Phase_AB_Voltage "Measured value of the voltage betwen phase A and Phase B";
CM_ SG_ 935 D2_Output_Voltage "The calculated value of the output voltage, in peak line-neutral volts";
CM_ SG_ 935 D1_DC_Bus_Voltage "The actual measured value of the DC bus voltage";
CM_ SG_ 934 D4_DC_Bus_Current "The Calculated DC Bus Current";
CM_ SG_ 934 D3_Phase_C_Current "The measured value of Phase C current";
CM_ SG_ 934 D2_Phase_B_Current "The measured value of Phase B current";
CM_ SG_ 934 D1_Phase_A_Current "The measured value of Phase A current";
CM_ SG_ 933 D4_Delta_Resolver_Filtered "Used in calibration of resolver angle adjustment.";
CM_ SG_ 933 D3_Electrical_Output_Frequency "The actual electrical frequency of the inverter";
CM_ SG_ 933 D2_Motor_Speed "The measured speed of the motor";
CM_ SG_ 933 D1_Motor_Angle_Electrical "The Electrical Angle of the motor as read by the encoder or resolver";
CM_ SG_ 932 D5_Digital_Input_5 "Status of Digital Input #5";
CM_ SG_ 932 D4_Digital_Input_4 "Status of Digital Input #4";
CM_ SG_ 932 D3_Digital_Input_3 "Status of Digital Input #3";
CM_ SG_ 932 D2_Digital_Input_2 "Status of Digital Input #2";
CM_ SG_ 932 D1_Digital_Input_1 "Status of Digital Input #1";
CM_ SG_ 932 D6_Digital_Input_6 "Status of Digital Input #6";
CM_ SG_ 932 D7_Digital_Input_7 "Status of Digital Input #7";
CM_ SG_ 932 D8_Digital_Input_8 "Status of Digital Input #8";
CM_ SG_ 931 D4_Analog_Input_4 "Voltage on Analog Input #4";
CM_ SG_ 931 D3_Analog_Input_3 "Voltage on Analog Input #3";
CM_ SG_ 931 D2_Analog_Input_2 "Voltage on Analog Input #2";
CM_ SG_ 931 D1_Analog_Input_1 "Voltage on Analog Input #1";
CM_ SG_ 930 D4_Torque_Shudder "Shudder compensation value of torque";
CM_ SG_ 930 D3_Motor_Temperature "Motor Temperature Sensor";
CM_ SG_ 930 D2_RTD5_Temperature "RTD 5 (PT1000) Temperature";
CM_ SG_ 930 D1_RTD4_Temperature "RTD 4 (PT1000) Temperature";
CM_ SG_ 929 D4_RTD3_Temperature "RTD input 3 (PT1000) Temperature";
CM_ SG_ 929 D3_RTD2_Temperature "RTD input 2 (PT1000) Temperature";
CM_ SG_ 929 D2_RTD1_Temperature "RTD input 1 (PT1000) Temperature";
CM_ SG_ 929 D1_Control_Board_Temperature "Control Board Temperature";
CM_ SG_ 928 D4_Gate_Driver_Board "Gate Driver Board Temperature";
CM_ SG_ 928 D3_Module_C "IGBT Module C Temperature";
CM_ SG_ 928 D2_Module_B "IGBT Module B Temperature";
CM_ SG_ 928 D1_Module_A "IGBT Module A Temperature";
CM_ SG_ 1197 D4_Iq_Command "The commanded Q-axis current";
CM_ SG_ 1197 D3_Id_Command "The commanded D-axis current";
CM_ SG_ 1197 D2_Flux_Weakening_Output "This is the current output of the flux regulator.";
CM_ SG_ 1197 D1_Modulation_Index "This is the modulation index. The scale factor is x100. To get the actual modulation index divide the value by 100.";
CM_ SG_ 1196 D3_Power_On_Timer "Updated every 3 msec. This will roll over in approximately 150 days!";
CM_ SG_ 1196 D2_Torque_Feedback "Estimated motor torque feedback";
CM_ SG_ 1196 D1_Commanded_Torque "The commanded Torque";
CM_ BO_ 1218 "To write a parameter use message 0x0C1 with byte #2 set to 1 (write). To read a parameter use message 0x0C1 with byte #2 to set 0 (read). ";
CM_ SG_ 1218 D2_Write_Success "0=Write failure, 1=Success";
CM_ SG_ 1218 D3_Data_Response "All EEPROM data is 16 bits and is contained in bytes 4 and 5. Bytes 6 and 7 should be ignored.";
CM_ SG_ 1218 D1_Parameter_Address_Response "Valid EEPROM Parameter CAN addresses are between 100 and 499.";
CM_ BO_ 1217 "To write a parameter use message 0x0C1 with byte #2 set to 1 (write). To read a parameter use message 0x0C1 with byte #2 to set 0 (read). ";
CM_ SG_ 1217 D3_Data_Command "All EEPROM data is 16 bits and is contained in bytes 4 and 5.";
CM_ SG_ 1217 D2_Read_Write_Command "0=Read, 1=Write";
CM_ SG_ 1217 D1_Parameter_Address_Command "Valid EEPROM Parameter CAN addresses are between 100 and 499.";
CM_ BO_ 1216 "The command message is used to transmit data to the controller. This message is sent from a user supplied external controller to the PMxxx controller.";
CM_ SG_ 1216 Inverter_Enable "0=Inverter OFF, 1 = Inverter ON";
CM_ SG_ 1216 Direction_Command "0=CW, 1=CCW as veiwed from the shaft end of the motor";
CM_ SG_ 1216 Speed_Command "Speed commandused when in speed mode";
CM_ SG_ 1216 Torque_Command "Torque command when in torque mode";
CM_ SG_ 1216 Inverter_Discharge "0=Discharge Disable,=Discharge Enable";
CM_ SG_ 1216 Torque_Limit_Command "Torque Limit, set to 0 to keep default";
CM_ SG_ 1216 Speed_Mode_Enable "0 = No change to mode, 1 = change to speed mode from torque mode";
CM_ SG_ 1195 D4_Run_Fault_Hi "Each bit represents a fault. Please refer to PM100 Users Manual for details.";
CM_ SG_ 1195 D2_Post_Fault_Hi "Each bit represents a fault. Please refer to PM100 Users Manual for details.";
CM_ SG_ 1195 D3_Run_Fault_Lo "Each bit represents a fault. Please refer to PM100 Users Manual for details.";
CM_ SG_ 1195 D1_Post_Fault_Lo "Each bit represents a fault. Please refer to PM100 Users Manual for details.";
CM_ SG_ 1194 D7_Direction_Command "1 = Forward0 = 'Reverse' if inverter enabled  & 'Stopped' if inverter is disabled";
CM_ SG_ 1194 D6_Inverter_Enable_State "0=Inverter Disabled, 1=Inverter Enabled";
CM_ SG_ 1194 D3_Relay_3_Status "0=OFF, 1=ON";
CM_ SG_ 1194 D3_Relay_4_Status "0=OFF, 1=ON";
CM_ SG_ 1194 D3_Relay_2_Status "0=OFF, 1=ON";
CM_ SG_ 1194 D4_Inverter_Run_Mode "0=Torque Mode, 1=Speed Mode";
CM_ SG_ 1194 D5_Inverter_Command_Mode "0=CAN mode, 1=VSM mode";
CM_ SG_ 1194 D3_Relay_1_Status "0=OFF, 1=ON";
CM_ SG_ 1194 D2_Inverter_State "Different states for the inverter state machine";
CM_ SG_ 1194 D1_VSM_State "Different states for the vehicle state machine";
CM_ SG_ 1194 D6_Inverter_Enable_Lockout "0=Lockout Disabled, 1=Lockout Enabled";
CM_ SG_ 1194 D4_Inverter_Discharge_State "0 = Disabled, 1 = Enabled, 2 = Speed Check, 3 = Active, 4 = Complete";
CM_ SG_ 1194 D3_Relay_5_Status "0=OFF, 1=ON";
CM_ SG_ 1194 D3_Relay_6_Status "0=OFF, 1=ON";
CM_ SG_ 1193 D4_Reference_Voltage_12_0 "12V Input Voltage";
CM_ SG_ 1193 D3_Reference_Voltage_5_0 "Transducer voltage";
CM_ SG_ 1193 D2_Reference_Voltage_2_5 "Internal reference voltage";
CM_ SG_ 1193 D1_Reference_Voltage_1_5 "Internal reference voltage";
CM_ SG_ 1192 D4_Iq "The measured Iq current";
CM_ SG_ 1192 D3_Id "The measured Id current";
CM_ SG_ 1192 D2_Flux_Feedback "The estimated flux";
CM_ SG_ 1192 D1_Flux_Command "The commanded flux";
CM_ SG_ 1191 D4_Phase_BC_Voltage "Measured value of the voltage between Phase B and Phase C";
CM_ SG_ 1191 D3_Phase_AB_Voltage "Measured value of the voltage betwen phase A and Phase B";
CM_ SG_ 1191 D2_Output_Voltage "The calculated value of the output voltage, in peak line-neutral volts";
CM_ SG_ 1191 D1_DC_Bus_Voltage "The actual measured value of the DC bus voltage";
CM_ SG_ 1190 D4_DC_Bus_Current "The Calculated DC Bus Current";
CM_ SG_ 1190 D3_Phase_C_Current "The measured value of Phase C current";
CM_ SG_ 1190 D2_Phase_B_Current "The measured value of Phase B current";
CM_ SG_ 1190 D1_Phase_A_Current "The measured value of Phase A current";
CM_ SG_ 1189 D4_Delta_Resolver_Filtered "Used in calibration of resolver angle adjustment.";
CM_ SG_ 1189 D3_Electrical_Output_Frequency "The actual electrical frequency of the inverter";
CM_ SG_ 1189 D2_Motor_Speed "The measured speed of the motor";
CM_ SG_ 1189 D1_Motor_Angle_Electrical "The Electrical Angle of the motor as read by the encoder or resolver";
CM_ SG_ 1188 D5_Digital_Input_5 "Status of Digital Input #5";
CM_ SG_ 1188 D4_Digital_Input_4 "Status of Digital Input #4";
CM_ SG_ 1188 D3_Digital_Input_3 "Status of Digital Input #3";
CM_ SG_ 1188 D2_Digital_Input_2 "Status of Digital Input #2";
CM_ SG_ 1188 D1_Digital_Input_1 "Status of Digital Input #1";
CM_ SG_ 1188 D6_Digital_Input_6 "Status of Digital Input #6";
CM_ SG_ 1188 D7_Digital_Input_7 "Status of Digital Input #7";
CM_ SG_ 1188 D8_Digital_Input_8 "Status of Digital Input #8";
CM_ SG_ 1187 D4_Analog_Input_4 "Voltage on Analog Input #4";
CM_ SG_ 1187 D3_Analog_Input_3 "Voltage on Analog Input #3";
CM_ SG_ 1187 D2_Analog_Input_2 "Voltage on Analog Input #2";
CM_ SG_ 1187 D1_Analog_Input_1 "Voltage on Analog Input #1";
CM_ SG_ 1186 D4_Torque_Shudder "Shudder compensation value of torque";
CM_ SG_ 1186 D3_Motor_Temperature "Motor Temperature Sensor";
CM_ SG_ 1186 D2_RTD5_Temperature "RTD 5 (PT1000) Temperature";
CM_ SG_ 1186 D1_RTD4_Temperature "RTD 4 (PT1000) Temperature";
CM_ SG_ 1185 D4_RTD3_Temperature "RTD input 3 (PT1000) Temperature";
CM_ SG_ 1185 D3_RTD2_Temperature "RTD input 2 (PT1000) Temperature";
CM_ SG_ 1185 D2_RTD1_Temperature "RTD input 1 (PT1000) Temperature";
CM_ SG_ 1185 D1_Control_Board_Temperature "Control Board Temperature";
CM_ SG_ 1184 D4_Gate_Driver_Board "Gate Driver Board Temperature";
CM_ SG_ 1184 D3_Module_C "IGBT Module C Temperature";
CM_ SG_ 1184 D2_Module_B "IGBT Module B Temperature";
CM_ SG_ 1184 D1_Module_A "IGBT Module A Temperature";

BA_DEF_  "BusType" STRING ;
BA_DEF_ BO_  "GenMsgCycleTime" INT 0 65535;
BA_DEF_ SG_  "GenSigStartValue" FLOAT -3.4E+038 3.4E+038;

BA_DEF_DEF_  "BusType" "CAN";
BA_DEF_DEF_  "GenMsgCycleTime" 0;
BA_DEF_DEF_  "GenSigStartValue" 0;

BA_ "GenMsgCycleTime" BO_ 514 10;
BA_ "GenMsgCycleTime" BO_ 516 10;
BA_ "GenMsgCycleTime" BO_ 513 10;
BA_ "GenMsgCycleTime" BO_ 517 10;
BA_ "GenMsgCycleTime" BO_ 518 10;
BA_ "GenMsgCycleTime" BO_ 515 10;
BA_ "GenMsgCycleTime" BO_ 512 10;
BA_ "GenMsgCycleTime" BO_ 940 10;
BA_ "GenMsgCycleTime" BO_ 962 10;
BA_ "GenMsgCycleTime" BO_ 961 10;
BA_ "GenMsgCycleTime" BO_ 960 5;
BA_ "GenMsgCycleTime" BO_ 939 100;
BA_ "GenMsgCycleTime" BO_ 938 100;
BA_ "GenMsgCycleTime" BO_ 937 100;
BA_ "GenMsgCycleTime" BO_ 936 10;
BA_ "GenMsgCycleTime" BO_ 935 10;
BA_ "GenMsgCycleTime" BO_ 934 10;
BA_ "GenMsgCycleTime" BO_ 933 10;
BA_ "GenMsgCycleTime" BO_ 932 10;
BA_ "GenMsgCycleTime" BO_ 931 10;
BA_ "GenMsgCycleTime" BO_ 930 100;
BA_ "GenMsgCycleTime" BO_ 929 100;
BA_ "GenMsgCycleTime" BO_ 928 100;
BA_ "GenMsgCycleTime" BO_ 1196 10;
BA_ "GenMsgCycleTime" BO_ 1218 10;
BA_ "GenMsgCycleTime" BO_ 1217 10;
BA_ "GenMsgCycleTime" BO_ 1216 5;
BA_ "GenMsgCycleTime" BO_ 1195 100;
BA_ "GenMsgCycleTime" BO_ 1194 100;
BA_ "GenMsgCycleTime" BO_ 1193 100;
BA_ "GenMsgCycleTime" BO_ 1192 10;
BA_ "GenMsgCycleTime" BO_ 1191 10;
BA_ "GenMsgCycleTime" BO_ 1190 10;
BA_ "GenMsgCycleTime" BO_ 1189 10;
BA_ "GenMsgCycleTime" BO_ 1188 10;
BA_ "GenMsgCycleTime" BO_ 1187 10;
BA_ "GenMsgCycleTime" BO_ 1186 100;
BA_ "GenMsgCycleTime" BO_ 1185 100;
BA_ "GenMsgCycleTime" BO_ 1184 100;

VAL_ 514 FSM_State 0 "GLV_ON" 1 "HV_EN" 2 "RTD" 3 "ERROR" ;
VAL_ 516 DIM_State 0 "GLV_ON" 1 "HV_EN" 2 "RTD" 3 "ERROR" ;
VAL_ 516 Requested_State 0 "GLV_ON" 1 "HV_EN" 2 "RTD" 3 "ERROR" ;
VAL_ 513 CC_State 0 "GLV_ON" 1 "HV_EN" 2 "RTD" 3 "ERROR" ;
VAL_ 517 AFC_State 0 "GLV_ON" 1 "HV_EN" 2 "RTD" 3 "ERROR" ;
VAL_ 518 TM_State 0 "GLV_ON" 1 "HV_EN" 2 "RTD" 3 "ERROR" ;
VAL_ 515 RSM_State 0 "GLV_ON" 1 "HV_EN" 2 "RTD" 3 "ERROR" ;
VAL_ 515 Pump_L_Status 1 "On" 0 "Off" ;
VAL_ 515 Pump_R_Status 1 "On" 0 "Off" ;
VAL_ 512 SM_State 0 "GLV_ON" 1 "HV_EN" 2 "RTD" 3 "ERROR" ;
VAL_ 512 Target_State 0 "GLV_ON" 1 "HV_EN" 2 "RTD" 3 "ERROR" ;
VAL_ 1527 BMS_Precharge_State 0 "Error" 1 "Idle" 2 "Measure" 3 "Precharge" 4 "Run" 5 "Enable Pack" ;

SIG_VALTYPE_ 1524 BMS_Pack_SOC_Ah : 1;
SIG_VALTYPE_ 1524 BMS_Pack_SOC_Percent : 1;
SIG_VALTYPE_ 1525 BMS_Balance_SOC_Ah : 1;
SIG_VALTYPE_ 1525 BMS_Balance_SOC_Percent : 1;
